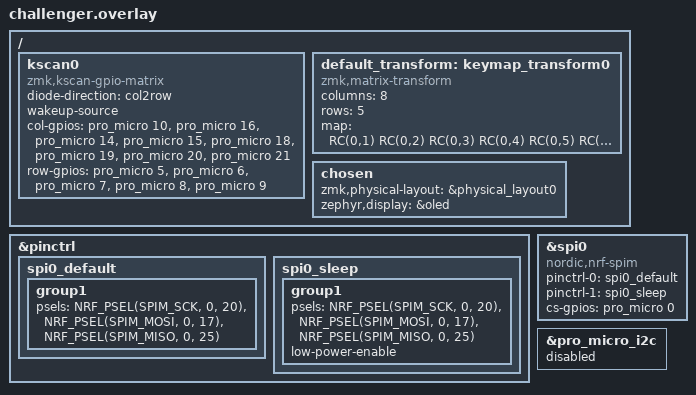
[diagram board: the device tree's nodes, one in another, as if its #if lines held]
#include <dt-bindings/zmk/matrix_transform.h>
#include <zephyr/sys/util.h>
#include "challenger-layouts.dtsi"

/ {
    kscan0: kscan0 {
        compatible = "zmk,kscan-gpio-matrix";
        diode-direction = "col2row";
        wakeup-source;

        col-gpios
            = <&pro_micro 10 GPIO_ACTIVE_HIGH>
            , <&pro_micro 16 GPIO_ACTIVE_HIGH>
            , <&pro_micro 14 GPIO_ACTIVE_HIGH>
            , <&pro_micro 15 GPIO_ACTIVE_HIGH>
            , <&pro_micro 18 GPIO_ACTIVE_HIGH>
            , <&pro_micro 19 GPIO_ACTIVE_HIGH>
            , <&pro_micro 20 GPIO_ACTIVE_HIGH>
            , <&pro_micro 21 GPIO_ACTIVE_HIGH>
            ;

        row-gpios
            = <&pro_micro 5 (GPIO_ACTIVE_HIGH | GPIO_PULL_DOWN)>
            , <&pro_micro 6 (GPIO_ACTIVE_HIGH | GPIO_PULL_DOWN)>
            , <&pro_micro 7 (GPIO_ACTIVE_HIGH | GPIO_PULL_DOWN)>
            , <&pro_micro 8 (GPIO_ACTIVE_HIGH | GPIO_PULL_DOWN)>
            , <&pro_micro 9 (GPIO_ACTIVE_HIGH | GPIO_PULL_DOWN)>
            ;
    };


    default_transform: keymap_transform0 {
        compatible = "zmk,matrix-transform";
        columns = <8>;
        rows = <5>;
        map = <
                    RC(0,1) RC(0,2) RC(0,3) RC(0,4) RC(0,5) RC(0,6) RC(0,7)
                    RC(1,1) RC(1,2) RC(1,3) RC(1,4) RC(1,5) RC(1,6) RC(1,7)
                    RC(2,1) RC(2,2) RC(2,3) RC(2,4) RC(2,5) RC(2,6) RC(2,7)
            RC(3,0) RC(3,1) RC(3,2) RC(3,3) RC(3,4) RC(3,5) RC(3,6) RC(3,7)
            RC(4,0) RC(4,1) RC(4,2)         RC(4,4) RC(4,5) RC(4,6)
        >;
    };

    chosen {
        zmk,physical-layout = &physical_layout0;
        zephyr,display = &oled;
    };
};

#if IS_ENABLED(CONFIG_CHALLENGER_HAS_NICE_VIEW_SHIELD)
// Taken from the nice_view_adapter shield, with the only change being the CS GPIO pin, changed from 1 to 0 to match the
// Challenger shield's wiring.
&pinctrl {
    spi0_default: spi0_default {
        group1 {
            psels = <NRF_PSEL(SPIM_SCK, 0, 20)>,
                <NRF_PSEL(SPIM_MOSI, 0, 17)>,
                <NRF_PSEL(SPIM_MISO, 0, 25)>;
        };
    };
    spi0_sleep: spi0_sleep {
        group1 {
            psels = <NRF_PSEL(SPIM_SCK, 0, 20)>,
                <NRF_PSEL(SPIM_MOSI, 0, 17)>,
                <NRF_PSEL(SPIM_MISO, 0, 25)>;
            low-power-enable;
        };
    };
};

nice_view_spi: &spi0 {
    compatible = "nordic,nrf-spim";
    pinctrl-0 = <&spi0_default>;
    pinctrl-1 = <&spi0_sleep>;
    pinctrl-names = "default", "sleep";
    cs-gpios = <&pro_micro 0 GPIO_ACTIVE_HIGH>;
};

&pro_micro_i2c {
    status = "disabled";
};
#else
&pro_micro_i2c {
    status = "okay";

    oled: oled@3c {
        compatible = "solomon,ssd1306fb";
        reg = <0x3c>;
        width = <128>;
        height = <32>;
        segment-offset = <0>;
        page-offset = <0>;
        display-offset = <0>;
        multiplex-ratio = <31>;
        prechargep = <0x22>;
        segment-remap;
        com-invdir;
        status = "okay";
    };
};
#endif
